VERSION ""

NS_ :

BS_:

BU_: WidebandController ECU

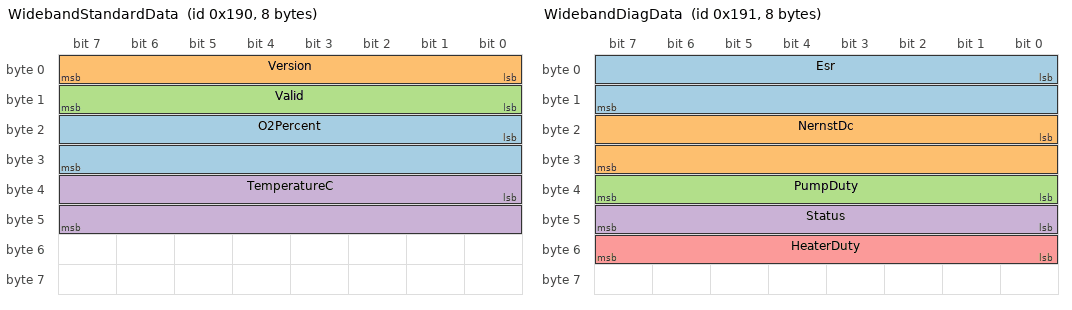
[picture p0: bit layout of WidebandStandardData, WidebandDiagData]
BO_ 400 WidebandStandardData: 8 WidebandController
 SG_ O2Percent : 16|16@1+ (0.01,0) [0|20.95] "%"  ECU
 SG_ Version : 0|8@1+ (1,0) [0|0] ""  ECU
 SG_ Valid : 8|8@1+ (1,0) [0|1] ""  ECU
 SG_ TemperatureC : 32|16@1+ (1,0) [0|1000] "deg C"  ECU

BO_ 401 WidebandDiagData: 8 WidebandController
 SG_ Esr : 0|16@1+ (1,0) [0|10000] "ohms"  ECU
 SG_ NernstDc : 16|16@1+ (0.001,0) [0|1.5] "volt"  ECU
 SG_ PumpDuty : 32|8@1+ (0.392157,0) [0|100] "%"  ECU
 SG_ Status : 40|8@1+ (1,0) [0|0] ""  ECU
 SG_ HeaterDuty : 48|8@1+ (0.392157,0) [0|100] "%"  ECU

BO_ 2398420992 WidebandControl: 2 ECU
 SG_ BatteryVoltage : 0|8@1+ (0.1,0) [0|25] "volt"  WidebandController
 SG_ HeaterEnable : 8|8@1+ (1,0) [0|1] ""  WidebandController

CM_ BO_ 400 "Increment ID by 2*N for the N-th controller (Standard/Diag block)";
CM_ SG_ 400 Version "Currently 0xA1 (O2% on StandardData; no ExtendedData)";
CM_ SG_ 400 Valid "Set to 1 when O2% is valid (heater closed-loop and nernst near target)";
CM_ SG_ 400 O2Percent "Free O2% from unclamped lambda: 20.95*(1-1/lambda), clamped >=0, x100";
CM_ BO_ 401 "Increment ID by 2*N for the N-th controller";
CM_ BO_ 2398420992 "Sent by ECU to control wideband controller";
CM_ SG_ 2398420992 BatteryVoltage "Provide system supply voltage for heater supply voltage compensation";
CM_ SG_ 2398420992 HeaterEnable "Set to 1 to allow sensor heating once engine runs";
